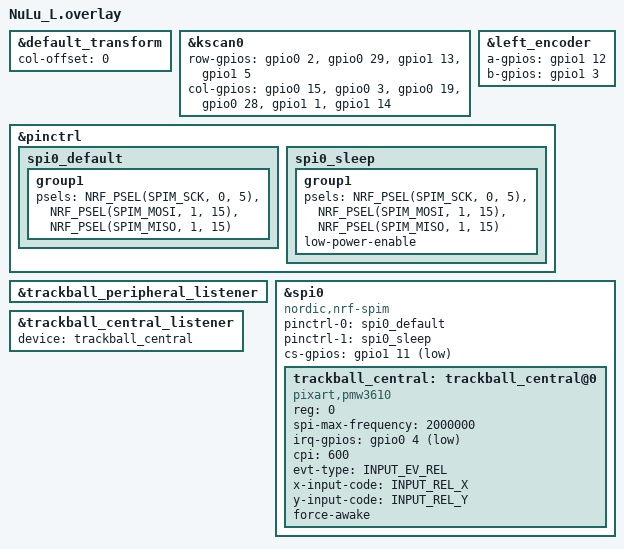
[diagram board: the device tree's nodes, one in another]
#include "NuLu.dtsi"
#include <zephyr/dt-bindings/input/input-event-codes.h>

&default_transform {
    col-offset = <0>;
};

&kscan0 {
    row-gpios
        = <&gpio0 2 (GPIO_ACTIVE_HIGH | GPIO_PULL_DOWN)>  /* Row0 */
        , <&gpio0 29 (GPIO_ACTIVE_HIGH | GPIO_PULL_DOWN)> /* Row1 */
        , <&gpio1 13 (GPIO_ACTIVE_HIGH | GPIO_PULL_DOWN)> /* Row2 */
        , <&gpio1 5 (GPIO_ACTIVE_HIGH | GPIO_PULL_DOWN)>  /* Row3 */
        ;

    col-gpios
        = <&gpio0 15 GPIO_ACTIVE_HIGH> /* Col0 */
        , <&gpio0 3 GPIO_ACTIVE_HIGH>  /* Col1 */
        , <&gpio0 19 GPIO_ACTIVE_HIGH> /* Col2 */
        , <&gpio0 28 GPIO_ACTIVE_HIGH> /* Col3 */
        , <&gpio1 1 GPIO_ACTIVE_HIGH>  /* Col4 */
        , <&gpio1 14 GPIO_ACTIVE_HIGH> /* Col5 */
        ;
};

&left_encoder {
    a-gpios = <&gpio1 12 (GPIO_ACTIVE_HIGH | GPIO_PULL_UP)>;
    b-gpios = <&gpio1 3 (GPIO_ACTIVE_HIGH | GPIO_PULL_UP)>;
    status = "okay";
};

&pinctrl {
    spi0_default: spi0_default {
        group1 {
            psels = <NRF_PSEL(SPIM_SCK, 0, 5)>,
                <NRF_PSEL(SPIM_MOSI, 1, 15)>,
                <NRF_PSEL(SPIM_MISO, 1, 15)>;
        };
    };

    spi0_sleep: spi0_sleep {
        group1 {
            psels = <NRF_PSEL(SPIM_SCK, 0, 5)>,
                <NRF_PSEL(SPIM_MOSI, 1, 15)>,
                <NRF_PSEL(SPIM_MISO, 1, 15)>;
            low-power-enable;
        };
    };
};

&trackball_peripheral_listener {
    status = "okay";
};

&spi0 {
    status = "okay";
    compatible = "nordic,nrf-spim";
    pinctrl-0 = <&spi0_default>;
    pinctrl-1 = <&spi0_sleep>;
    pinctrl-names = "default", "sleep";
    cs-gpios = <&gpio1 11 GPIO_ACTIVE_LOW>;

    trackball_central: trackball_central@0 {
        status = "okay";
        compatible = "pixart,pmw3610";
        reg = <0>;
        spi-max-frequency = <2000000>;
        irq-gpios = <&gpio0 4 (GPIO_ACTIVE_LOW | GPIO_PULL_UP)>;
        cpi = <600>;
        evt-type = <INPUT_EV_REL>;
        x-input-code = <INPUT_REL_X>;
        y-input-code = <INPUT_REL_Y>;
        force-awake;
    };
};

// Overrides for the input listener node
&trackball_central_listener {
    status = "okay";
    device = <&trackball_central>;
};
